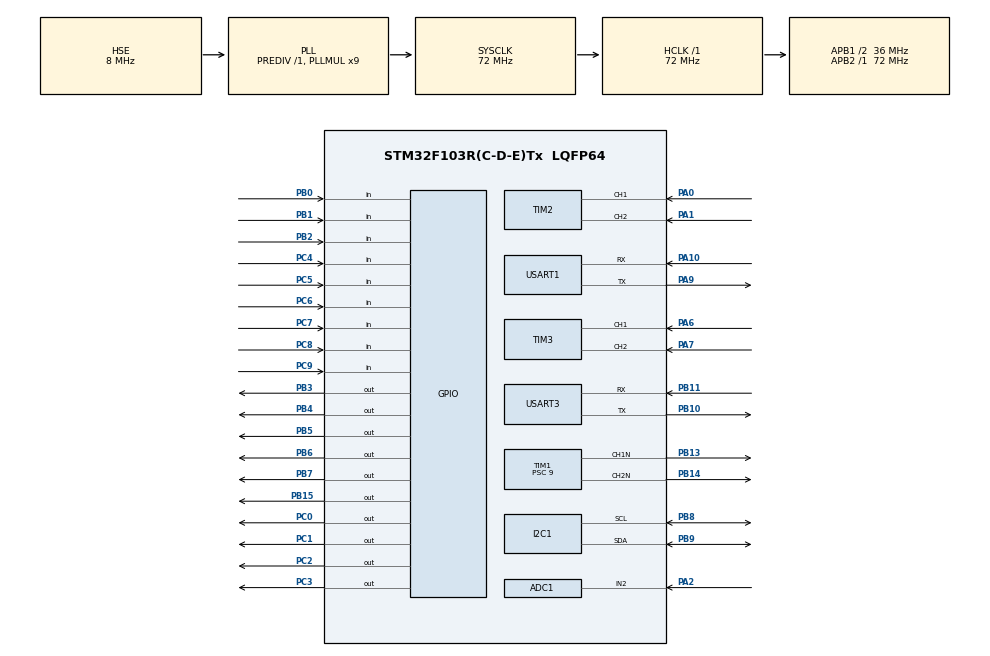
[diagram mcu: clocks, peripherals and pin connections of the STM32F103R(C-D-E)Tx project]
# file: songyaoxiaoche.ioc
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ADC1.Channel-2\#ChannelRegularConversion=ADC_CHANNEL_2
ADC1.NbrOfConversionFlag=1
ADC1.Rank-2\#ChannelRegularConversion=1
ADC1.SamplingTime-2\#ChannelRegularConversion=ADC_SAMPLETIME_1CYCLE_5
ADC1.master=1
Mcu.Family=STM32F1
Mcu.Name=STM32F103R(C-D-E)Tx
Mcu.Package=LQFP64
NVIC.PriorityGroup=NVIC_PRIORITYGROUP_4
PA0-WKUP.Signal=S_TIM2_CH1_ETR
PA1.Signal=S_TIM2_CH2
PA10.Mode=Asynchronous
PA10.Signal=USART1_RX
PA13.Mode=Serial_Wire
PA13.Signal=SYS_JTMS-SWDIO
PA14.Mode=Serial_Wire
PA14.Signal=SYS_JTCK-SWCLK
PA2.Signal=ADCx_IN2
PA6.Signal=S_TIM3_CH1
PA7.Signal=S_TIM3_CH2
PA9.Mode=Asynchronous
PA9.Signal=USART1_TX
PB0.Signal=GPIO_Input
PB1.Signal=GPIO_Input
PB10.Mode=Asynchronous
PB10.Signal=USART3_TX
PB11.Mode=Asynchronous
PB11.Signal=USART3_RX
PB13.Mode=PWM Generation1 CH1N
PB13.Signal=TIM1_CH1N
PB14.Mode=PWM Generation2 CH2N
PB14.Signal=TIM1_CH2N
PB15.Signal=GPIO_Output
PB2.Signal=GPIO_Input
PB3.GPIO_Speed=GPIO_SPEED_FREQ_HIGH
PB3.Signal=GPIO_Output
PB4.GPIO_Speed=GPIO_SPEED_FREQ_HIGH
PB4.Signal=GPIO_Output
PB5.GPIO_Speed=GPIO_SPEED_FREQ_HIGH
PB5.Signal=GPIO_Output
PB6.GPIO_Speed=GPIO_SPEED_FREQ_HIGH
PB6.Signal=GPIO_Output
PB7.GPIO_Speed=GPIO_SPEED_FREQ_HIGH
PB7.Signal=GPIO_Output
PB8.Mode=I2C
PB8.Signal=I2C1_SCL
PB9.Mode=I2C
PB9.Signal=I2C1_SDA
PC0.Signal=GPIO_Output
PC1.Signal=GPIO_Output
PC2.Signal=GPIO_Output
PC3.Signal=GPIO_Output
PC4.Signal=GPIO_Input
PC5.Signal=GPIO_Input
PC6.Signal=GPIO_Input
PC7.Signal=GPIO_Input
PC8.Signal=GPIO_Input
PC9.Signal=GPIO_Input
PD0-OSC_IN.Mode=HSE-External-Oscillator
PD0-OSC_IN.Signal=RCC_OSC_IN
PD1-OSC_OUT.Mode=HSE-External-Oscillator
PD1-OSC_OUT.Signal=RCC_OSC_OUT
ProjectManager.HeapSize=0x200
ProjectManager.StackSize=0x400
ProjectManager.TargetToolchain=MDK-ARM V5.32
RCC.ADCPresc=RCC_ADCPCLK2_DIV6
RCC.AHBFreq_Value=72000000
RCC.APB1CLKDivider=RCC_HCLK_DIV2
RCC.APB1Freq_Value=36000000
RCC.APB1TimFreq_Value=72000000
RCC.APB2Freq_Value=72000000
RCC.APB2TimFreq_Value=72000000
RCC.HCLKFreq_Value=72000000
RCC.PLLMUL=RCC_PLL_MUL9
RCC.PLLSourceVirtual=RCC_PLLSOURCE_HSE
RCC.SYSCLKFreq_VALUE=72000000
RCC.SYSCLKSource=RCC_SYSCLKSOURCE_PLLCLK
RCC.USBFreq_Value=72000000
SH.ADCx_IN2.0=ADC1_IN2,IN2
SH.S_TIM2_CH1_ETR.0=TIM2_CH1,Encoder_Interface
SH.S_TIM2_CH2.0=TIM2_CH2,Encoder_Interface
SH.S_TIM3_CH1.0=TIM3_CH1,Encoder_Interface
SH.S_TIM3_CH2.0=TIM3_CH2,Encoder_Interface
TIM1.Channel-PWM\ Generation1\ CH1N=TIM_CHANNEL_1
TIM1.Channel-PWM\ Generation2\ CH2N=TIM_CHANNEL_2
TIM1.Period=7199
TIM1.Prescaler=9
USART1.VirtualMode=VM_ASYNC
USART3.VirtualMode=VM_ASYNC
VP_TIM1_VS_ClockSourceINT.Mode=Internal
board=custom

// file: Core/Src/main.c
/* USER CODE BEGIN Header */
/**
  ******************************************************************************
  * @file           : main.c
  * @brief          : Main program body
  ******************************************************************************
  * @attention
  *
  * Copyright (c) 2022 STMicroelectronics.
  * All rights reserved.
  *
  * This software is licensed under terms that can be found in the LICENSE file
  * in the root directory of this software component.
  * If no LICENSE file comes with this software, it is provided AS-IS.
  *
  ******************************************************************************
  */
/* USER CODE END Header */
#include "main.h"
#include "adc.h"
#include "i2c.h"
#include "tim.h"
#include "usart.h"
#include "gpio.h"

/* USER CODE BEGIN Includes */
#include "uart.h"
#include "oled.h"
/* USER CODE END Includes */

void SystemClock_Config(void);

/* USER CODE BEGIN 0 */
void HAL_TIM_PeriodElapsedCallback(TIM_HandleTypeDef* htim)
{
  static uint16_t t;
  if (htim->Instance == TIM1)
  {

  }
}
/* USER CODE END 0 */

int main(void)
{
  /* USER CODE BEGIN 1 */
  int32_t a=0;
  /* USER CODE END 1 */

  /* MCU Configuration--------------------------------------------------------*/

  /* Reset of all peripherals, Initializes the Flash interface and the Systick. */
  HAL_Init();

  /* Configure the system clock */
  SystemClock_Config();

  /* Initialize all configured peripherals */
  MX_GPIO_Init();
  MX_ADC1_Init();
  MX_I2C1_Init();
  MX_TIM1_Init();
  MX_TIM2_Init();
  MX_TIM3_Init();
  MX_USART1_UART_Init();
  MX_USART3_UART_Init();
  /* USER CODE BEGIN 2 */
  HAL_TIM_Base_Start_IT(&htim1);
  /* USER CODE END 2 */

  /* Infinite loop */
  /* USER CODE BEGIN WHILE */
  OLED_Init();
  while (1)
  {
    OLED_ShowString(0, 0, "fdsghghfdhfdhr");
    Transmit_uart();
    a++;
    HAL_Delay(3000);

    /* USER CODE END WHILE */

  }
}

void SystemClock_Config(void)
{
  RCC_OscInitTypeDef RCC_OscInitStruct = {0};
  RCC_ClkInitTypeDef RCC_ClkInitStruct = {0};
  RCC_PeriphCLKInitTypeDef PeriphClkInit = {0};

  /** Initializes the RCC Oscillators according to the specified parameters
  * in the RCC_OscInitTypeDef structure.
  */
  RCC_OscInitStruct.OscillatorType = RCC_OSCILLATORTYPE_HSE;
  RCC_OscInitStruct.HSEState = RCC_HSE_ON;
  RCC_OscInitStruct.HSEPredivValue = RCC_HSE_PREDIV_DIV1;
  RCC_OscInitStruct.HSIState = RCC_HSI_ON;
  RCC_OscInitStruct.PLL.PLLState = RCC_PLL_ON;
  RCC_OscInitStruct.PLL.PLLSource = RCC_PLLSOURCE_HSE;
  RCC_OscInitStruct.PLL.PLLMUL = RCC_PLL_MUL9;
  if (HAL_RCC_OscConfig(&RCC_OscInitStruct) != HAL_OK)
  {
    Error_Handler();
  }

  /** Initializes the CPU, AHB and APB buses clocks
  */
  RCC_ClkInitStruct.ClockType = RCC_CLOCKTYPE_HCLK|RCC_CLOCKTYPE_SYSCLK
                              |RCC_CLOCKTYPE_PCLK1|RCC_CLOCKTYPE_PCLK2;
  RCC_ClkInitStruct.SYSCLKSource = RCC_SYSCLKSOURCE_PLLCLK;
  RCC_ClkInitStruct.AHBCLKDivider = RCC_SYSCLK_DIV1;
  RCC_ClkInitStruct.APB1CLKDivider = RCC_HCLK_DIV2;
  RCC_ClkInitStruct.APB2CLKDivider = RCC_HCLK_DIV1;

  if (HAL_RCC_ClockConfig(&RCC_ClkInitStruct, FLASH_LATENCY_2) != HAL_OK)
  {
    Error_Handler();
  }
  PeriphClkInit.PeriphClockSelection = RCC_PERIPHCLK_ADC;
  PeriphClkInit.AdcClockSelection = RCC_ADCPCLK2_DIV6;
  if (HAL_RCCEx_PeriphCLKConfig(&PeriphClkInit) != HAL_OK)
  {
    Error_Handler();
  }
}

void Error_Handler(void)
{
  __disable_irq();
  while (1)
  {
  }
}
